AUTOSAR XML (schema 4-0-3)
standard types defined: Boolean, UInt16, UInt32, UInt8
package /AUTOSAR_Platform/DataConstrs
  range DC_Boolean: raw 0..1
  range DC_UInt16: raw 0..65535
  range DC_UInt8: raw 0..255
package /PATAC/MSM/ComponentTypes
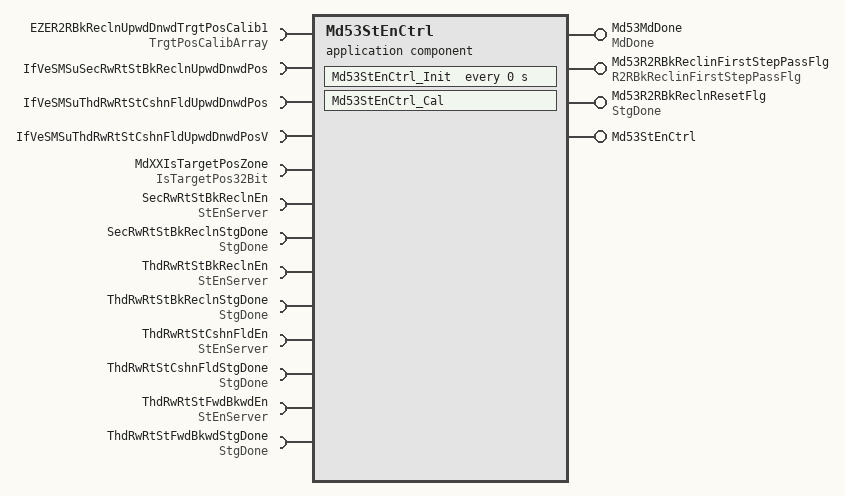
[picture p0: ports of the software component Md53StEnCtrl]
  application sw component type Md53StEnCtrl
    4 x provide port:
      Md53MdDone: nonqueued-sender-com-spec{data-element=MdDone/Val, init-value=0}, provided-interface=MdDone
      Md53R2RBkReclinFirstStepPassFlg: nonqueued-sender-com-spec{data-element=R2RBkReclinFirstStepPassFlg/Val, init-value=0}, provided-interface=R2RBkReclinFirstStepPassFlg
      Md53R2RBkReclnResetFlg: nonqueued-sender-com-spec{data-element=StgDone/Val, init-value=0}, provided-interface=StgDone
      Md53StEnCtrl: server-com-spec{operation=Cal, queue-length=1}, provided-interface=Md53StEnCtrl
    13 x require port:
      EZER2RBkReclnUpwdDnwdTrgtPosCalib1: nonqueued-receiver-com-spec{data-element=TrgtPosArray, filter=data-filter-type=ALWAYS, init-value=[4095, 4095, 4095]}, required-interface=TrgtPosCalibArray
      IfVeSMSuSecRwRtStBkReclnUpwdDnwdPos: nonqueued-receiver-com-spec{data-element=IfVeSMSuSecRwRtStBkReclnUpwdDnwdPos/Val, filter=data-filter-type=ALWAYS, init-value=0}, required-interface=IfVeSMSuSecRwRtStBkReclnUpwdDnwdPos
      IfVeSMSuThdRwRtStCshnFldUpwdDnwdPos: nonqueued-receiver-com-spec{data-element=IfVeSMSuThdRwRtStCshnFldUpwdDnwdPos/Val, filter=data-filter-type=ALWAYS, init-value=0}, required-interface=IfVeSMSuThdRwRtStCshnFldUpwdDnwdPos
      IfVeSMSuThdRwRtStCshnFldUpwdDnwdPosV: nonqueued-receiver-com-spec{data-element=IfVeSMSuThdRwRtStCshnFldUpwdDnwdPosV/Val, filter=data-filter-type=ALWAYS, init-value=0}, required-interface=IfVeSMSuThdRwRtStCshnFldUpwdDnwdPosV
      MdXXIsTargetPosZone: nonqueued-receiver-com-spec{data-element=IsTargetPos32Bit/Val, filter=data-filter-type=ALWAYS, init-value=0}, required-interface=IsTargetPos32Bit
      SecRwRtStBkReclnEn: required-com-specs=[Clear, Get, Set], required-interface=StEnServer
      SecRwRtStBkReclnStgDone: nonqueued-receiver-com-spec{data-element=StgDone/Val, filter=data-filter-type=ALWAYS, init-value=0}, required-interface=StgDone
      ThdRwRtStBkReclnEn: required-com-specs=[Clear, Get, Set], required-interface=StEnServer
      ThdRwRtStBkReclnStgDone: nonqueued-receiver-com-spec{data-element=StgDone/Val, filter=data-filter-type=ALWAYS, init-value=0}, required-interface=StgDone
      ThdRwRtStCshnFldEn: required-com-specs=[Clear, Get, Set], required-interface=StEnServer
      ThdRwRtStCshnFldStgDone: nonqueued-receiver-com-spec{data-element=StgDone/Val, filter=data-filter-type=ALWAYS, init-value=0}, required-interface=StgDone
      ThdRwRtStFwdBkwdEn: required-com-specs=[Clear, Get, Set], required-interface=StEnServer
      ThdRwRtStFwdBkwdStgDone: nonqueued-receiver-com-spec{data-element=StgDone/Val, filter=data-filter-type=ALWAYS, init-value=0}, required-interface=StgDone
    behavior Md53StEnCtrl_InternalBehavior
      operation invoked event OIT_Md53StEnCtrl_Cal_Md53StEnCtrl_Cal: start-on-event=Md53StEnCtrl_Cal, operation=Md53StEnCtrl.Cal
      timing event Md53StEnCtrl_InitEvent: start-on-event=Md53StEnCtrl_Init, period=0
      runnable Md53StEnCtrl_Cal
        data-receive-point-by-arguments:
          9 x access:
            REC_EZER2RBkReclnUpwdDnwdTrgtPosCalib1_TrgtPosArray: accessed-variable=EZER2RBkReclnUpwdDnwdTrgtPosCalib1.TrgtPosArray
            REC_IfVeSMSuSecRwRtStBkReclnUpwdDnwdPos_Val: accessed-variable=IfVeSMSuSecRwRtStBkReclnUpwdDnwdPos.Val
            REC_IfVeSMSuThdRwRtStCshnFldUpwdDnwdPos_Val: accessed-variable=IfVeSMSuThdRwRtStCshnFldUpwdDnwdPos.Val
            REC_IfVeSMSuThdRwRtStCshnFldUpwdDnwdPosV_Val: accessed-variable=IfVeSMSuThdRwRtStCshnFldUpwdDnwdPosV.Val
            REC_MdXXIsTargetPosZone_Val: accessed-variable=MdXXIsTargetPosZone.Val
            REC_SecRwRtStBkReclnStgDone_Val: accessed-variable=SecRwRtStBkReclnStgDone.Val
            REC_ThdRwRtStBkReclnStgDone_Val: accessed-variable=ThdRwRtStBkReclnStgDone.Val
            REC_ThdRwRtStCshnFldStgDone_Val: accessed-variable=ThdRwRtStCshnFldStgDone.Val
            REC_ThdRwRtStFwdBkwdStgDone_Val: accessed-variable=ThdRwRtStFwdBkwdStgDone.Val
        data-send-points:
          access SEND_Md53MdDone_Val: accessed-variable=Md53MdDone.Val
          access SEND_Md53R2RBkReclinFirstStepPassFlg_Val: accessed-variable=Md53R2RBkReclinFirstStepPassFlg.Val
          access SEND_Md53R2RBkReclnResetFlg_Val: accessed-variable=Md53R2RBkReclnResetFlg.Val
        8 x sync call, all with timeout=0:
          SC_SecRwRtStBkReclnEn_Clear: operation=SecRwRtStBkReclnEn.Clear
          SC_SecRwRtStBkReclnEn_Set: operation=SecRwRtStBkReclnEn.Set
          SC_ThdRwRtStBkReclnEn_Clear: operation=ThdRwRtStBkReclnEn.Clear
          SC_ThdRwRtStBkReclnEn_Set: operation=ThdRwRtStBkReclnEn.Set
          SC_ThdRwRtStCshnFldEn_Clear: operation=ThdRwRtStCshnFldEn.Clear
          SC_ThdRwRtStCshnFldEn_Set: operation=ThdRwRtStCshnFldEn.Set
          SC_ThdRwRtStFwdBkwdEn_Clear: operation=ThdRwRtStFwdBkwdEn.Clear
          SC_ThdRwRtStFwdBkwdEn_Set: operation=ThdRwRtStFwdBkwdEn.Set
      runnable Md53StEnCtrl_Init
  swc implementation Md53StEnCtrl_Implementation: behavior=Md53StEnCtrl_InternalBehavior
    code-descriptors:
      code Default: artifact-descriptors=autosar-engineering-object={short-label=Default, category=SWSRC}
package /PATAC/MSM/ModeAdjust/DataType
  impl type TrgtPosCalibArray: category=ARRAY, sw-calibration-access=READ-ONLY, type-emitter=RTE  # 0:pos 1:max 2:min
    element Element: array-size=3, array-size-semantics=FIXED-SIZE, implementation-data-type=UInt16, invalid-value=0
package /PATAC/MSM/ModeAdjust/Interfaces
  sender receiver interface IfVeSMSuThdRwRtStCshnFldUpwdDnwdPos: invalidation-policy{data-element=IfVeSMSuThdRwRtStCshnFldUpwdDnwdPos/Val, handle-invalid=DONT-INVALIDATE}
    data Val: type=UInt16
  sender receiver interface IfVeSMSuThdRwRtStCshnFldUpwdDnwdPosV: invalidation-policy{data-element=IfVeSMSuThdRwRtStCshnFldUpwdDnwdPosV/Val, handle-invalid=DONT-INVALIDATE}
    data Val: type=Boolean
package /PATAC/MSM/ModeAdjust/PortInterface
  client server interface Md53StEnCtrl
    operation Cal
      arg FirstTrig: type=Boolean, direction=IN, server-argument-impl-policy=USE-ARGUMENT-TYPE
  client server interface StEnServer
    operation Clear
      arg data: type=UInt8, direction=IN, server-argument-impl-policy=USE-ARGUMENT-TYPE
    operation Get
      arg data: type=UInt32, direction=OUT, server-argument-impl-policy=USE-ARGUMENT-TYPE
    operation Set
      arg data: type=UInt8, direction=IN, server-argument-impl-policy=USE-ARGUMENT-TYPE
  5 x sender receiver interface:
    IsTargetPos32Bit: invalidation-policy{data-element=IsTargetPos32Bit/Val, handle-invalid=DONT-INVALIDATE}
      data Val: type=UInt32
    MdDone: invalidation-policy{data-element=MdDone/Val, handle-invalid=DONT-INVALIDATE}
      data Val: type=UInt8
    R2RBkReclinFirstStepPassFlg: invalidation-policy{data-element=R2RBkReclinFirstStepPassFlg/Val, handle-invalid=DONT-INVALIDATE}
      data Val: type=Boolean
    StgDone: invalidation-policy{data-element=StgDone/Val, handle-invalid=DONT-INVALIDATE}
      data Val: type=Boolean
    TrgtPosCalibArray: invalidation-policy{data-element=TrgtPosArray, handle-invalid=DONT-INVALIDATE}
      data TrgtPosArray: type=TrgtPosCalibArray  # 0:Pos 1:Max 2:Min
package /PATAC/MSM/PortInterfaces
  sender receiver interface IfVeSMSuSecRwRtStBkReclnUpwdDnwdPos: invalidation-policy{data-element=IfVeSMSuSecRwRtStBkReclnUpwdDnwdPos/Val, handle-invalid=DONT-INVALIDATE}
    data Val: type=UInt16
